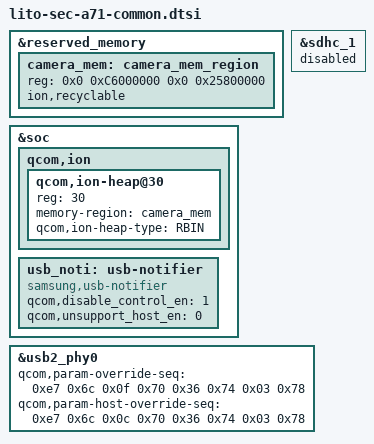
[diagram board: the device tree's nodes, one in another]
/* Copyright (c) 2019, The Linux Foundation. All rights reserved.
 *
 * This program is free software; you can redistribute it and/or modify
 * it under the terms of the GNU General Public License version 2 and
 * only version 2 as published by the Free Software Foundation.
 *
 * This program is distributed in the hope that it will be useful,
 * but WITHOUT ANY WARRANTY; without even the implied warranty of
 * MERCHANTABILITY or FITNESS FOR A PARTICULAR PURPOSE.  See the
 * GNU General Public License for more details.
 */

&reserved_memory {
       camera_mem: camera_mem_region {
               reg = <0x0 0xC6000000 0x0 0x25800000>;
               ion,recyclable;
       };
};

&soc {
       qcom,ion {
               qcom,ion-heap@30 { /* CAMERA HEAP  */
                       reg = <30>;
                       memory-region = <&camera_mem>;
                       qcom,ion-heap-type = "RBIN";
               };
       };
 }; 

&soc {

	usb_noti: usb-notifier {
		compatible = "samsung,usb-notifier";
		qcom,disable_control_en = <1>;
		qcom,unsupport_host_en = <0>;
	};
};

&sdhc_1 {
	status = "disabled";
};

&usb2_phy0 {
	qcom,param-override-seq =
		<0xe7 0x6c
		0x0f 0x70
		0x36 0x74
		0x03 0x78>;
	qcom,param-host-override-seq =
		<0xe7 0x6c
		0x0c 0x70
		0x36 0x74
		0x03 0x78>;
};
